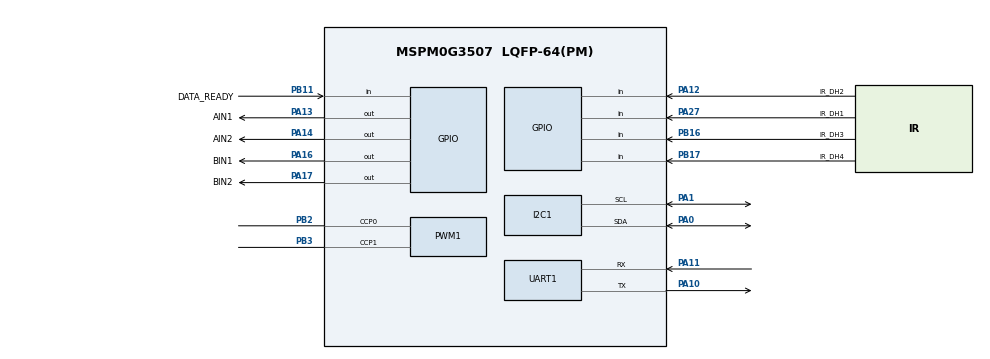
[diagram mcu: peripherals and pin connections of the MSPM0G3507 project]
/**
 * AI AGENTS: Do not edit this file directly. There is no validation or error feedback when
 * editing manually — mistakes will be silent until the file is loaded in SysConfig.
 * Use the SysConfig MCP server instead to make changes with immediate error reporting.
 *
 * These arguments were used when this file was generated. They will be automatically applied on subsequent loads
 * via the GUI or CLI. Run CLI with '--help' for additional information on how to override these arguments.
 * @cliArgs --device "MSPM0G350X" --part "Default" --package "LQFP-64(PM)" --product "mspm0_sdk@2.11.00.07"
 * @v2CliArgs --device "MSPM0G3507" --package "LQFP-64(PM)" --product "mspm0_sdk@2.11.00.07"
 * @versions {"tool":"1.28.0+4696"}
 */

/**
 * Import the modules used in this configuration.
 */
const GPIO   = scripting.addModule("/ti/driverlib/GPIO", {}, false);
const GPIO1  = GPIO.addInstance();
const GPIO2  = GPIO.addInstance();
const GPIO3  = GPIO.addInstance();
const I2C    = scripting.addModule("/ti/driverlib/I2C", {}, false);
const I2C1   = I2C.addInstance();
const PWM    = scripting.addModule("/ti/driverlib/PWM", {}, false);
const PWM1   = PWM.addInstance();
const SYSCTL = scripting.addModule("/ti/driverlib/SYSCTL");
const UART   = scripting.addModule("/ti/driverlib/UART", {}, false);
const UART1  = UART.addInstance();

/**
 * Write custom configuration values to the imported modules.
 */
GPIO1.$name                         = "GPIO_MOTOR_DIR";
GPIO1.associatedPins.create(4);
GPIO1.associatedPins[0].$name       = "AIN1";
GPIO1.associatedPins[0].pin.$assign = "PA13";
GPIO1.associatedPins[1].$name       = "AIN2";
GPIO1.associatedPins[1].pin.$assign = "PA14";
GPIO1.associatedPins[2].$name       = "BIN1";
GPIO1.associatedPins[2].pin.$assign = "PA16";
GPIO1.associatedPins[3].$name       = "BIN2";
GPIO1.associatedPins[3].pin.$assign = "PA17";

const Board = scripting.addModule("/ti/driverlib/Board", {}, false);

GPIO2.$name                         = "GPIO_LINE_SENSOR";
GPIO2.associatedPins.create(4);
GPIO2.associatedPins[0].$name       = "IR_DH1";
GPIO2.associatedPins[0].direction   = "INPUT";
GPIO2.associatedPins[0].pin.$assign = "PA27";
GPIO2.associatedPins[1].$name       = "IR_DH2";
GPIO2.associatedPins[1].direction   = "INPUT";
GPIO2.associatedPins[1].pin.$assign = "PA12";
GPIO2.associatedPins[2].$name       = "IR_DH3";
GPIO2.associatedPins[2].direction   = "INPUT";
GPIO2.associatedPins[2].pin.$assign = "PB16";
GPIO2.associatedPins[3].$name       = "IR_DH4";
GPIO2.associatedPins[3].direction   = "INPUT";
GPIO2.associatedPins[3].pin.$assign = "PB17";

GPIO3.$name                         = "GPIO_MPU6050";
GPIO3.associatedPins[0].direction   = "INPUT";
GPIO3.associatedPins[0].interruptEn = true;
GPIO3.associatedPins[0].polarity    = "RISE";
GPIO3.associatedPins[0].$name       = "DATA_READY";
GPIO3.associatedPins[0].pin.$assign = "PB11";

I2C1.$name                             = "I2C_MPU6050";
I2C1.basicEnableController             = true;
I2C1.basicControllerStandardBusSpeed   = "Fast";
I2C1.peripheral.sdaPin.$assign         = "PA0";
I2C1.peripheral.sclPin.$assign         = "PA1";
I2C1.sdaPinConfig.$name                = "ti_driverlib_gpio_GPIOPinGeneric0";
I2C1.sdaPinConfig.hideOutputInversion  = scripting.forceWrite(false);
I2C1.sdaPinConfig.onlyInternalResistor = scripting.forceWrite(false);
I2C1.sdaPinConfig.passedPeripheralType = scripting.forceWrite("Digital");
I2C1.sclPinConfig.$name                = "ti_driverlib_gpio_GPIOPinGeneric1";
I2C1.sclPinConfig.hideOutputInversion  = scripting.forceWrite(false);
I2C1.sclPinConfig.onlyInternalResistor = scripting.forceWrite(false);
I2C1.sclPinConfig.passedPeripheralType = scripting.forceWrite("Digital");

PWM1.$name                              = "PWM_MOTOR";
PWM1.timerCount                         = 8000;
PWM1.peripheral.$assign                 = "TIMA1";
PWM1.peripheral.ccp0Pin.$assign         = "PB2";
PWM1.peripheral.ccp1Pin.$assign         = "PB3";
PWM1.PWM_CHANNEL_0.$name                = "ti_driverlib_pwm_PWMTimerCC0";
PWM1.PWM_CHANNEL_1.$name                = "ti_driverlib_pwm_PWMTimerCC1";
PWM1.ccp0PinConfig.$name                = "ti_driverlib_gpio_GPIOPinGeneric4";
PWM1.ccp0PinConfig.direction            = scripting.forceWrite("OUTPUT");
PWM1.ccp0PinConfig.hideOutputInversion  = scripting.forceWrite(false);
PWM1.ccp0PinConfig.onlyInternalResistor = scripting.forceWrite(false);
PWM1.ccp0PinConfig.passedPeripheralType = scripting.forceWrite("Digital");
PWM1.ccp1PinConfig.$name                = "ti_driverlib_gpio_GPIOPinGeneric5";
PWM1.ccp1PinConfig.direction            = scripting.forceWrite("OUTPUT");
PWM1.ccp1PinConfig.hideOutputInversion  = scripting.forceWrite(false);
PWM1.ccp1PinConfig.onlyInternalResistor = scripting.forceWrite(false);
PWM1.ccp1PinConfig.passedPeripheralType = scripting.forceWrite("Digital");

SYSCTL.forceDefaultClkConfig = true;
SYSCTL.clockTreeEn           = true;

UART1.$name                            = "UART_CONSOLE";
UART1.targetBaudRate                   = 115200;
UART1.enableFIFO                       = true;
UART1.enabledInterrupts                = ["TX"];
UART1.peripheral.rxPin.$assign         = "PA11";
UART1.peripheral.txPin.$assign         = "PA10";
UART1.txPinConfig.$name                = "ti_driverlib_gpio_GPIOPinGeneric2";
UART1.txPinConfig.direction            = scripting.forceWrite("OUTPUT");
UART1.txPinConfig.hideOutputInversion  = scripting.forceWrite(false);
UART1.txPinConfig.onlyInternalResistor = scripting.forceWrite(false);
UART1.txPinConfig.passedPeripheralType = scripting.forceWrite("Digital");
UART1.rxPinConfig.$name                = "ti_driverlib_gpio_GPIOPinGeneric3";
UART1.rxPinConfig.hideOutputInversion  = scripting.forceWrite(false);
UART1.rxPinConfig.onlyInternalResistor = scripting.forceWrite(false);
UART1.rxPinConfig.passedPeripheralType = scripting.forceWrite("Digital");

/**
 * Pinmux solution for unlocked pins/peripherals. This ensures that minor changes to the automatic solver in a future
 * version of the tool will not impact the pinmux you originally saw.  These lines can be completely deleted in order to
 * re-solve from scratch.
 */
Board.peripheral.$suggestSolution          = "DEBUGSS";
Board.peripheral.swclkPin.$suggestSolution = "PA20";
Board.peripheral.swdioPin.$suggestSolution = "PA19";
I2C1.peripheral.$suggestSolution           = "I2C0";
UART1.peripheral.$suggestSolution          = "UART0";
